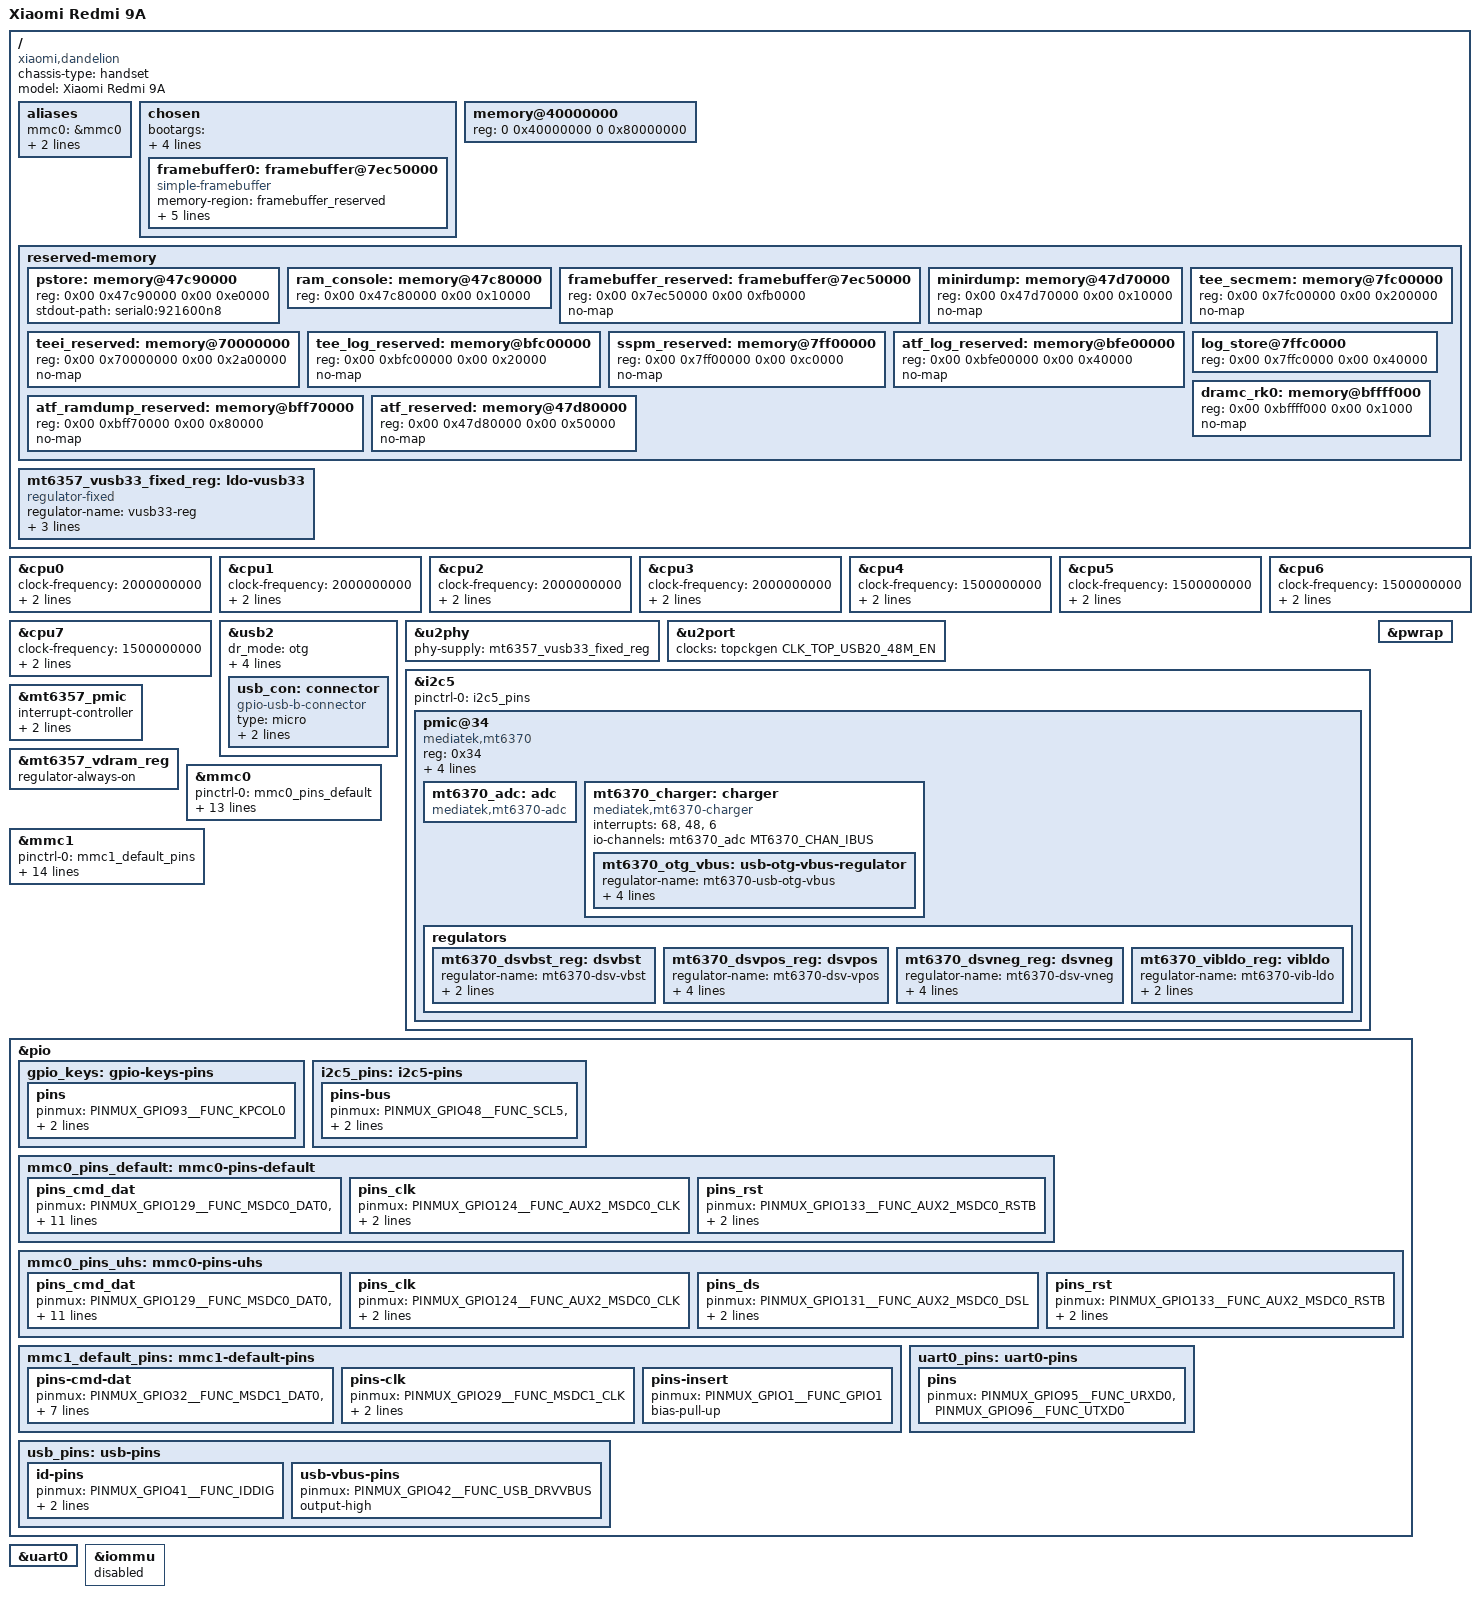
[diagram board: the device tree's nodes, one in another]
// SPDX-License-Identifier: GPL-2.0
//
// Device Tree Source for Xiaomi Redmi 9A // (dandelion)
//
// Copyright (c) 2025 Ryo "evilMyQueen" Yamada <evilMyQueen@mainlining.org>
//
// nya

/dts-v1/;

#include <dt-bindings/gpio/gpio.h>
#include <dt-bindings/iio/adc/mediatek,mt6370_adc.h>
#include <dt-bindings/input/input.h>
#include <dt-bindings/leds/common.h>
#include <dt-bindings/pinctrl/mediatek,mt6765-pinfunc.h>

#include "mt6765.dtsi"
#include "mt6357.dtsi"

/ {
	chassis-type = "handset";
	compatible = "xiaomi,dandelion", "mediatek,mt6762", "mediatek,mt6765";
	model = "Xiaomi Redmi 9A";

	aliases {
		mmc0 = &mmc0;
		mmc1 = &mmc1;
		serial0 = &uart0;
	};

	chosen {
		bootargs = "earlycon=mtk8250,0x11002000 console=ttyS0,921600n1 console=tty0 console=ttyGS0 clk_ignore_unused regulator_ignore_unused pd_ignore_unused PMOS_NOSPLASH";
		#address-cells = <2>;
		#size-cells = <2>;
		ranges;
		stdout-path = "serial0:921600n8";
		linux,initrd-start = <0x51100000>;
		linux,initrd-end = <0x517ffd98>;
		framebuffer0: framebuffer@7ec50000 {
			compatible = "simple-framebuffer";
			memory-region = <&framebuffer_reserved>;
			power-domains = <&spm MT6765_POWER_DOMAIN_DISP>;
			width = <736>;
			height = <1600>;
			stride = <((720 + 16) * 4)>;
			format = "a8r8g8b8";
			status = "okay";
		};
	};

	memory@40000000 {
		device_type = "memory";
		reg = <0 0x40000000 0 0x80000000>;
	};

	reserved-memory {
		#address-cells = <2>;
		#size-cells = <2>;
		ranges;

		pstore: memory@47c90000 {
			reg = <0x00 0x47c90000 0x00 0xe0000>;
			stdout-path = "serial0:921600n8";
		};

		ram_console: memory@47c80000 {
			reg = <0x00 0x47c80000 0x00 0x10000>;
		};

		framebuffer_reserved: framebuffer@7ec50000 {
			reg = <0x00 0x7ec50000 0x00 0xfb0000>;
			no-map;
		};

		minirdump: memory@47d70000 {
			reg = <0x00 0x47d70000 0x00 0x10000>;
			no-map;
		};

		teei_reserved: memory@70000000 {
			reg = <0x00 0x70000000 0x00 0x2a00000>;
			no-map;
		};

		tee_log_reserved: memory@bfc00000 {
			reg = <0x00 0xbfc00000 0x00 0x20000>;
			no-map;
		};

		sspm_reserved: memory@7ff00000 {
			reg = <0x00 0x7ff00000 0x00 0xc0000>;
			no-map;
		};

		tee_secmem: memory@7fc00000 {
			reg = <0x00 0x7fc00000 0x00 0x200000>;
			no-map;
		};

		atf_log_reserved: memory@bfe00000 {
			reg = <0x00 0xbfe00000 0x00 0x40000>;
			no-map;
		};

		atf_ramdump_reserved: memory@bff70000 {
			reg = <0x00 0xbff70000 0x00 0x80000>;
			no-map;
		};

		atf_reserved: memory@47d80000 {
			reg = <0x00 0x47d80000 0x00 0x50000>;
			no-map;
		};

		log_store@7ffc0000 {
			reg = <0x00 0x7ffc0000 0x00 0x40000>;
		};

		dramc_rk0: memory@bffff000 {
			reg = <0x00 0xbffff000 0x00 0x1000>;
			no-map;
		};
	};

//	vbus_reg: vbus-reg {
//		compatible = "regulator-fixed";
//		regulator-name = "usb_vbus";
//		regulator-min-microvolt = <5000000>;
//		regulator-max-microvolt = <5000000>;
//	};
//
	mt6357_vusb33_fixed_reg: ldo-vusb33 {
		compatible = "regulator-fixed";
		regulator-name = "vusb33-reg";
		regulator-min-microvolt = <3300000>;
		regulator-max-microvolt = <3300000>;
		regulator-enable-ramp-delay = <264>;

	};
};

&cpu0 {
	clock-frequency = <2000000000>;
	proc-supply = <&mt6357_vproc_reg>;
	sram-supply = <&mt6357_vsram_proc_reg>;
};

&cpu1 {
	clock-frequency = <2000000000>;
	proc-supply = <&mt6357_vproc_reg>;
	sram-supply = <&mt6357_vsram_proc_reg>;
};

&cpu2 {
	clock-frequency = <2000000000>;
	proc-supply = <&mt6357_vproc_reg>;
	sram-supply = <&mt6357_vsram_proc_reg>;
};

&cpu3 {
	clock-frequency = <2000000000>;
	proc-supply = <&mt6357_vproc_reg>;
	sram-supply = <&mt6357_vsram_proc_reg>;
};

&cpu4 {
	clock-frequency = <1500000000>;
	proc-supply = <&mt6357_vproc_reg>;
	sram-supply = <&mt6357_vsram_proc_reg>;
};

&cpu5 {
	clock-frequency = <1500000000>;
	proc-supply = <&mt6357_vproc_reg>;
	sram-supply = <&mt6357_vsram_proc_reg>;
};

&cpu6 {
	clock-frequency = <1500000000>;
	proc-supply = <&mt6357_vproc_reg>;
	sram-supply = <&mt6357_vsram_proc_reg>;
};

&cpu7 {
	clock-frequency = <1500000000>;
	proc-supply = <&mt6357_vproc_reg>;
	sram-supply = <&mt6357_vsram_proc_reg>;
};

&usb2 {
	status = "okay";

	usb_con: connector {
		compatible = "usb-b-connector";
		type = "micro";
	};
};

&u2phy {
	status = "okay";
	phy-supply = <&mt6357_vusb33_fixed_reg>;

};

&u2port {
	clocks = <&topckgen CLK_TOP_USB20_48M_EN>;
};



&i2c5 {
	status = "okay";

	pinctrl-0 = <&i2c5_pins>;
	pinctrl-names = "default";

	pmic@34 {
		compatible = "mediatek,mt6370";
		reg = <0x34>;
		wakeup-source;
		interrupts-extended = <&pio 3 IRQ_TYPE_LEVEL_LOW>;
phy-supply = <&mt6357_vusb33_fixed_reg>;
		interrupt-controller;
		#interrupt-cells = <1>;

		mt6370_adc: adc {
			compatible = "mediatek,mt6370-adc";
			#io-channel-cells = <1>;
		};
//
//		mt6370_backlight: backlight {
//			compatible = "mediatek,mt6370-backlight";
//
//			max-brightness = <1024>;
//			default-brightness = <1024>;
//
//			mediatek,bled-channel-use = /bits/ 8 <15>;
//		};

		mt6370_charger: charger {
			compatible = "mediatek,mt6370-charger";
			interrupt-names = "uvp_d_evt", "attach_i", "mivr";
			interrupts = <68>, <48>, <6>;
			io-channels = <&mt6370_adc MT6370_CHAN_IBUS>;

			mt6370_otg_vbus: usb-otg-vbus-regulator {
				regulator-name = "mt6370-usb-otg-vbus";
				regulator-min-microvolt = <4350000>;
				regulator-max-microvolt = <5800000>;
				regulator-min-microamp = <500000>;
				regulator-max-microamp = <3000000>;
			};
		};

//		mt6370_indicator: indicator {
//			compatible = "mediatek,mt6370-indicator";
//			#address-cells = <1>;
//			#size-cells = <0>;
//
//			status = "disabled";
//		};
//
//		mt6370_flashlight: flashlight {
//			compatible = "mediatek,mt6370-flashlight";
//			#address-cells = <1>;
//			#size-cells = <0>;
//
//			led@0 {
//				reg = <0>;
//				led-sources = <0>;
//				function = LED_FUNCTION_FLASH;
//				color = <LED_COLOR_ID_WHITE>;
//				function-enumerator = <1>;
//				led-max-microamp = <200000>;
//				flash-max-microamp = <500000>;
//				flash-max-timeout-us = <1248000>;
//			};
//
//			led@1 {
//				reg = <1>;
//				led-sources = <1>;
//				function = LED_FUNCTION_FLASH;
//				color = <LED_COLOR_ID_WHITE>;
//				function-enumerator = <2>;
//				led-max-microamp = <200000>;
//				flash-max-microamp = <500000>;
//				flash-max-timeout-us = <1248000>;
//			};
//		};
//
//		tcpc {
//			compatible = "mediatek,mt6370-tcpc";
//			interrupts-extended = <&pio 4 IRQ_TYPE_LEVEL_LOW>;
//
//			status = "disabled";
//		};

		regulators {
			mt6370_dsvbst_reg: dsvbst {
				regulator-name = "mt6370-dsv-vbst";
				regulator-min-microvolt = <4000000>;
				regulator-max-microvolt = <6200000>;
			};

			mt6370_dsvpos_reg: dsvpos {
				regulator-name = "mt6370-dsv-vpos";
				regulator-min-microvolt = <4000000>;
				regulator-max-microvolt = <6000000>;
				regulator-boot-on;
				regulator-always-on;
			};

			mt6370_dsvneg_reg: dsvneg {
				regulator-name = "mt6370-dsv-vneg";
				regulator-min-microvolt = <4000000>;
				regulator-max-microvolt = <6000000>;
				regulator-boot-on;
				regulator-always-on;
			};

			mt6370_vibldo_reg: vibldo {
				regulator-name = "mt6370-vib-ldo";
				regulator-min-microvolt = <1600000>;
				regulator-max-microvolt = <4000000>;
			};
		};
	};
};

&mt6357_pmic {
	interrupt-controller;
	interrupt-parent = <&pio>;
	interrupts = <144 IRQ_TYPE_LEVEL_HIGH>;
	#interrupt-cells = <2>;
};

&mt6357_vdram_reg {
	regulator-always-on;
};

&mmc0 {
	status = "okay";
	pinctrl-names = "default", "state_uhs";
	pinctrl-0 = <&mmc0_pins_default>;
	pinctrl-1 = <&mmc0_pins_uhs>;
	bus-width = <8>;
	cap-mmc-highspeed;
	mmc-ddr-1_8v;
	mmc-hs200-1_8v;
	mmc-hs400-1_8v;
	cap-mmc-hw-reset;
//	no-sdio;no-sd;
	supports-cqe;
	cap-mmc-hw-reset;
	max-frequency = <200000000>;
	non-removable;
	vmmc-supply = <&mt6357_vemc_reg>;
	vqmmc-supply = <&mt6357_vio18_reg>;
	hs400-ds-delay = <0x12814>;
};

&mmc1 {
	status = "okay";
	pinctrl-names = "default", "state_uhs";
	pinctrl-0 = <&mmc1_default_pins>;
	pinctrl-1 = <&mmc1_default_pins>;
	bus-width = <4>;
	cap-sd-highspeed;
	cd-gpios = <&pio 1 0>;
	max-frequency = <200000000>;
	no-mmc;
	no-sdio;
	sd-uhs-ddr50;
	sd-uhs-sdr104;
	sd-uhs-sdr12;
	sd-uhs-sdr25;
	sd-uhs-sdr50;
	vmmc-supply = <&mt6357_vmch_reg>;
	vqmmc-supply = <&mt6357_vmc_reg>;
};

&pwrap {
	status = "okay";
};

&pio {
	gpio_keys: gpio-keys-pins {
		pins {
			pinmux = <PINMUX_GPIO93__FUNC_KPCOL0>;
			bias-pull-up;
			input-enable;
		};
	};

	i2c5_pins: i2c5-pins {
		pins-bus {
			pinmux = <PINMUX_GPIO48__FUNC_SCL5>,
				 <PINMUX_GPIO49__FUNC_SDA5>;
			bias-disable;
		};
	};

	mmc0_pins_default: mmc0-pins-default {
		pins_cmd_dat {
			pinmux = <PINMUX_GPIO129__FUNC_MSDC0_DAT0>,
				 <PINMUX_GPIO127__FUNC_MSDC0_DAT1>,
				 <PINMUX_GPIO126__FUNC_MSDC0_DAT2>,
				 <PINMUX_GPIO132__FUNC_AUX1_MSDC0_DAT3>,
				 <PINMUX_GPIO123__FUNC_MSDC0_DAT4>,
				 <PINMUX_GPIO125__FUNC_MSDC0_DAT5>,
				 <PINMUX_GPIO128__FUNC_MSDC0_DAT6>,
				 <PINMUX_GPIO130__FUNC_AUX2_MSDC0_DAT7>,
				 <PINMUX_GPIO122__FUNC_AUX2_MSDC0_CMD>;
			input-enable;
			drive-strength = <3>;
			bias-pull-up = <MTK_PUPD_SET_R1R0_01>;
		};

		pins_clk {
			pinmux = <PINMUX_GPIO124__FUNC_AUX2_MSDC0_CLK>;
			drive-strength = <3>;
			bias-pull-down = <MTK_PUPD_SET_R1R0_10>;
		};

		pins_rst {
			pinmux = <PINMUX_GPIO133__FUNC_AUX2_MSDC0_RSTB>;
			drive-strength = <3>;
			bias-pull-down = <MTK_PUPD_SET_R1R0_01>;
		};
	};

	mmc0_pins_uhs: mmc0-pins-uhs {
		pins_cmd_dat {
			pinmux = <PINMUX_GPIO129__FUNC_MSDC0_DAT0>,
				 <PINMUX_GPIO127__FUNC_MSDC0_DAT1>,
				 <PINMUX_GPIO126__FUNC_MSDC0_DAT2>,
				 <PINMUX_GPIO132__FUNC_AUX1_MSDC0_DAT3>,
				 <PINMUX_GPIO123__FUNC_MSDC0_DAT4>,
				 <PINMUX_GPIO125__FUNC_MSDC0_DAT5>,
				 <PINMUX_GPIO128__FUNC_MSDC0_DAT6>,
				 <PINMUX_GPIO130__FUNC_AUX2_MSDC0_DAT7>,
				 <PINMUX_GPIO122__FUNC_AUX2_MSDC0_CMD>;
			input-enable;
			drive-strength = <4>;
			bias-pull-up = <MTK_PUPD_SET_R1R0_01>;
		};

		pins_clk {
			pinmux = <PINMUX_GPIO124__FUNC_AUX2_MSDC0_CLK>;
			drive-strength = <4>;
			bias-pull-down = <MTK_PUPD_SET_R1R0_10>;
		};

		pins_ds {
			pinmux = <PINMUX_GPIO131__FUNC_AUX2_MSDC0_DSL>;
			drive-strength = <4>;
			bias-pull-down = <MTK_PUPD_SET_R1R0_10>;
		};

		pins_rst {
			pinmux = <PINMUX_GPIO133__FUNC_AUX2_MSDC0_RSTB>;
			drive-strength = <3>;
			bias-pull-down = <MTK_PUPD_SET_R1R0_01>;
		};
	};

	mmc1_default_pins: mmc1-default-pins {
		pins-cmd-dat {
			pinmux = <PINMUX_GPIO32__FUNC_MSDC1_DAT0>,
				 <PINMUX_GPIO34__FUNC_MSDC1_DAT1>,
				 <PINMUX_GPIO33__FUNC_MSDC1_DAT2>,
				 <PINMUX_GPIO31__FUNC_MSDC1_DAT3>,
				 <PINMUX_GPIO30__FUNC_MSDC1_CMD>;
			input-enable;
			drive-strength = <3>;
			bias-pull-up = <MTK_PUPD_SET_R1R0_01>;
		};

		pins-clk {
			pinmux = <PINMUX_GPIO29__FUNC_MSDC1_CLK>;
			drive-strength = <3>;
			bias-pull-down = <MTK_PUPD_SET_R1R0_10>;
		};

		pins-insert {
			pinmux = <PINMUX_GPIO1__FUNC_GPIO1>;
			bias-pull-up;
		};
	};

	uart0_pins: uart0-pins {
		pins {
			pinmux = <PINMUX_GPIO95__FUNC_URXD0>,
					 <PINMUX_GPIO96__FUNC_UTXD0>;
		};
	};

	usb_pins: usb-pins {
		id-pins {
			pinmux = <PINMUX_GPIO41__FUNC_IDDIG>;
			input-enable;
			bias-pull-up;
		};

		usb-vbus-pins {
			pinmux = <PINMUX_GPIO42__FUNC_USB_DRVVBUS>;
			output-high;
		};
	};
};

&usb2 {
  status = "okay";

  dr_mode = "otg";
  maximum-speed = "high-speed";
  pinctrl-0 = <&usb_pins>;
  pinctrl-names = "default";
  role-switch-default-mode = "peripheral";
  usb-role-switch;

  usb_con: connector {
    compatible = "gpio-usb-b-connector", "usb-b-connector";
    type = "micro";
    id-gpios = <&pio 41 GPIO_ACTIVE_HIGH>;
    vbus-supply = <&mt6370_otg_vbus>;
  };
};

&u2phy {
  status = "okay";

};

&uart0 {
	status = "okay";
};

&iommu {
	status = "disabled";
};

